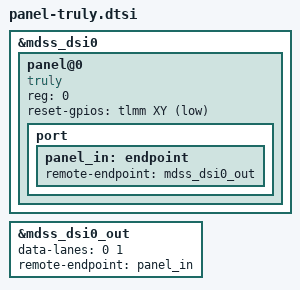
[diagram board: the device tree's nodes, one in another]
&mdss_dsi0 {
	panel@0 {
		compatible = "truly";
		reg = <0>;

		reset-gpios = <&tlmm XY GPIO_ACTIVE_LOW>;

		port {
			panel_in: endpoint {
				remote-endpoint = <&mdss_dsi0_out>;
			};
		};
	};
};

&mdss_dsi0_out {
	data-lanes = <0 1>;
	remote-endpoint = <&panel_in>;
};
